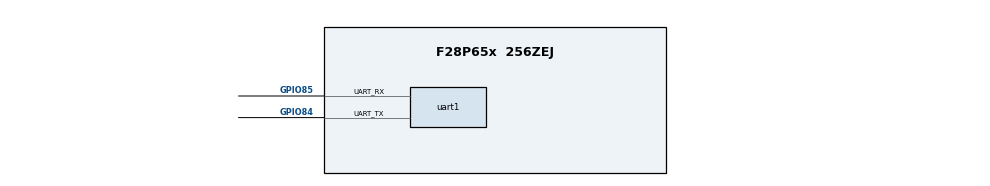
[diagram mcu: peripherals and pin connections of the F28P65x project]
/**
 * @cliArgs --device "F28P65x" --package "256ZEJ" --part "F28P65x_256ZEJ" --context "CPU1" --product "C2000WARE@5.01.00.00"
 * @versions {"tool":"1.19.0+3288"}
 */

/**
 * Import the modules used in this configuration.
 */
const dma   = scripting.addModule("/driverlib/dma.js", {}, false);
const dma1  = dma.addInstance();
const dma2  = dma.addInstance();
const uart  = scripting.addModule("/driverlib/uart.js", {}, false);
const uart1 = uart.addInstance();

/**
 * Write custom configuration values to the imported modules.
 */
dma1.$name                  = "myDMA0";
dma1.dmaBase                = "DMA_CH5_BASE";
dma1.enableTriggers         = true;
dma1.triggerSource          = "DMA_TRIGGER_UARTATX";
dma1.useInterrupts          = true;
dma1.registerInterrupts     = true;
dma1.enableInterrupts       = true;
dma1.interruptMode          = "DMA_INT_AT_END";
dma1.srcAddressInputMode    = "VARIABLE";
dma1.srcAddressVariable     = "txAddr";
dma1.destAddressInputMode   = "VARIABLE";
dma1.destAddressVariable    = "drAddr";
dma1.burstSize              = 2;
dma1.transferSize           = 16;
dma1.srcBurstStep           = 1;
dma1.srcTransferStep        = 1;
dma1.dmaInt.enableInterrupt = true;

dma2.$name                  = "myDMA1";
dma2.dmaBase                = "DMA_CH6_BASE";
dma2.enableTriggers         = true;
dma2.triggerSource          = "DMA_TRIGGER_UARTARX";
dma2.useInterrupts          = true;
dma2.registerInterrupts     = true;
dma2.enableInterrupts       = true;
dma2.interruptMode          = "DMA_INT_AT_END";
dma2.srcAddressInputMode    = "VARIABLE";
dma2.srcAddressVariable     = "drAddr";
dma2.destAddressInputMode   = "VARIABLE";
dma2.destAddressVariable    = "rxAddr";
dma2.burstSize              = 2;
dma2.transferSize           = 16;
dma2.destBurstStep          = 1;
dma2.destTransferStep       = 1;
dma2.dmaInt.enableInterrupt = true;

uart1.$name                   = "myUART0";
uart1.loopback                = true;
uart1.enInterrupt             = false;
uart1.fen                     = true;
uart1.uart.$assign            = "UARTA";
uart1.uart.uart_txPin.$assign = "GPIO84";
uart1.uart.uart_rxPin.$assign = "GPIO85";
